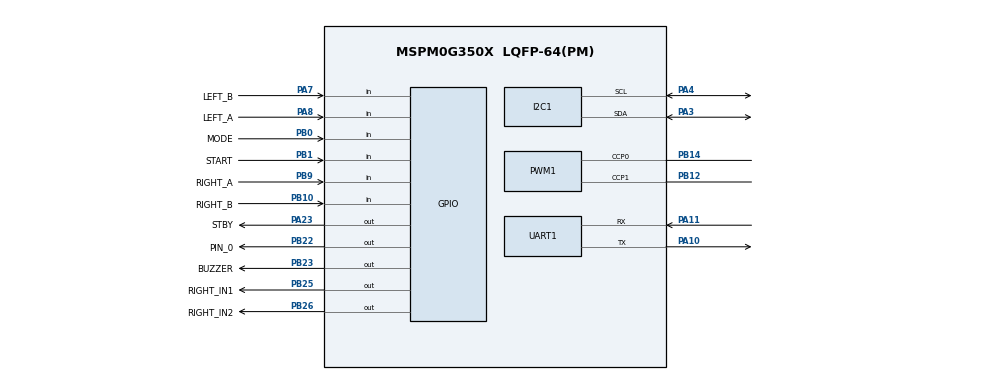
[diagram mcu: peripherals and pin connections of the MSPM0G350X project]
/**
 * @cliArgs --device "MSPM0G350X" --part "Default" --package "LQFP-64(PM)" --product "mspm0_sdk@2.10.00.04"
 * @versions {"tool":"1.27.1+4634"}
 */

/**
 * Import the modules used in this configuration.
 */
const GPIO          = scripting.addModule("/ti/driverlib/GPIO", {}, false);
const GPIO1         = GPIO.addInstance();
const GPIO2         = GPIO.addInstance();
const GPIO3         = GPIO.addInstance();
const GPIO4         = GPIO.addInstance();
const GPIO5         = GPIO.addInstance();
const GPIO6         = GPIO.addInstance();
const GPIO7         = GPIO.addInstance();
const GPIO8         = GPIO.addInstance();
const I2C           = scripting.addModule("/ti/driverlib/I2C", {}, false);
const I2C1          = I2C.addInstance();
const PWM           = scripting.addModule("/ti/driverlib/PWM", {}, false);
const PWM1          = PWM.addInstance();
const SYSCTL        = scripting.addModule("/ti/driverlib/SYSCTL");
const TIMER         = scripting.addModule("/ti/driverlib/TIMER", {}, false);
const TIMER1        = TIMER.addInstance();
const UART          = scripting.addModule("/ti/driverlib/UART", {}, false);
const UART1         = UART.addInstance();
const ProjectConfig = scripting.addModule("/ti/project_config/ProjectConfig");

/**
 * Write custom configuration values to the imported modules.
 */
GPIO1.$name                              = "MOTOR_LEFT";
GPIO1.port                               = "PORTA";
GPIO1.associatedPins.create(2);
GPIO1.associatedPins[0].assignedPin      = "24";
GPIO1.associatedPins[0].$name            = "LEFT_IN1";
GPIO1.associatedPins[0].internalResistor = "PULL_UP";
GPIO1.associatedPins[1].assignedPin      = "25";
GPIO1.associatedPins[1].$name            = "LEFT_IN2";
GPIO1.associatedPins[1].internalResistor = "PULL_UP";

const Board = scripting.addModule("/ti/driverlib/Board", {}, false);

GPIO2.$name                              = "MOTOR_RIGHT";
GPIO2.port                               = "PORTB";
GPIO2.associatedPins.create(2);
GPIO2.associatedPins[0].$name            = "RIGHT_IN1";
GPIO2.associatedPins[0].assignedPin      = "25";
GPIO2.associatedPins[0].internalResistor = "PULL_UP";
GPIO2.associatedPins[0].pin.$assign      = "PB25";
GPIO2.associatedPins[1].$name            = "RIGHT_IN2";
GPIO2.associatedPins[1].assignedPin      = "26";
GPIO2.associatedPins[1].internalResistor = "PULL_UP";
GPIO2.associatedPins[1].pin.$assign      = "PB26";

GPIO3.$name                          = "MOTOR_ENABLE";
GPIO3.port                           = "PORTA";
GPIO3.associatedPins[0].$name        = "STBY";
GPIO3.associatedPins[0].assignedPin  = "23";
GPIO3.associatedPins[0].initialValue = "SET";
GPIO3.associatedPins[0].pin.$assign  = "PA23";

GPIO4.$name                               = "ENCODER_LEFT";
GPIO4.port                                = "PORTA";
GPIO4.associatedPins.create(2);
GPIO4.associatedPins[0].$name             = "LEFT_A";
GPIO4.associatedPins[0].direction         = "INPUT";
GPIO4.associatedPins[0].assignedPin       = "8";
GPIO4.associatedPins[0].internalResistor  = "PULL_UP";
GPIO4.associatedPins[0].interruptEn       = true;
GPIO4.associatedPins[0].interruptPriority = "1";
GPIO4.associatedPins[0].polarity          = "RISE_FALL";
GPIO4.associatedPins[0].pin.$assign       = "PA8";
GPIO4.associatedPins[1].$name             = "LEFT_B";
GPIO4.associatedPins[1].direction         = "INPUT";
GPIO4.associatedPins[1].assignedPin       = "7";
GPIO4.associatedPins[1].internalResistor  = "PULL_UP";
GPIO4.associatedPins[1].interruptEn       = true;
GPIO4.associatedPins[1].interruptPriority = "1";
GPIO4.associatedPins[1].polarity          = "RISE_FALL";
GPIO4.associatedPins[1].pin.$assign       = "PA7";

GPIO5.$name                               = "ENCODER_RIGHT";
GPIO5.port                                = "PORTB";
GPIO5.associatedPins.create(2);
GPIO5.associatedPins[0].$name             = "RIGHT_A";
GPIO5.associatedPins[0].direction         = "INPUT";
GPIO5.associatedPins[0].assignedPin       = "9";
GPIO5.associatedPins[0].internalResistor  = "PULL_UP";
GPIO5.associatedPins[0].interruptEn       = true;
GPIO5.associatedPins[0].interruptPriority = "1";
GPIO5.associatedPins[0].polarity          = "RISE_FALL";
GPIO5.associatedPins[0].pin.$assign       = "PB9";
GPIO5.associatedPins[1].$name             = "RIGHT_B";
GPIO5.associatedPins[1].direction         = "INPUT";
GPIO5.associatedPins[1].assignedPin       = "10";
GPIO5.associatedPins[1].internalResistor  = "PULL_UP";
GPIO5.associatedPins[1].interruptEn       = true;
GPIO5.associatedPins[1].interruptPriority = "1";
GPIO5.associatedPins[1].polarity          = "RISE_FALL";
GPIO5.associatedPins[1].pin.$assign       = "PB10";

GPIO6.$name                              = "LED";
GPIO6.port                               = "PORTB";
GPIO6.associatedPins[0].$name            = "PIN_0";
GPIO6.associatedPins[0].internalResistor = "PULL_UP";
GPIO6.associatedPins[0].initialValue     = "SET";
GPIO6.associatedPins[0].pin.$assign      = "PB22";

GPIO7.$name                              = "H2024_BUTTONS";
GPIO7.port                               = "PORTB";
GPIO7.associatedPins.create(2);
GPIO7.associatedPins[0].$name            = "MODE";
GPIO7.associatedPins[0].direction        = "INPUT";
GPIO7.associatedPins[0].assignedPin      = "0";
GPIO7.associatedPins[0].internalResistor = "PULL_UP";
GPIO7.associatedPins[0].pin.$assign      = "PB0";
GPIO7.associatedPins[1].$name            = "START";
GPIO7.associatedPins[1].direction        = "INPUT";
GPIO7.associatedPins[1].assignedPin      = "1";
GPIO7.associatedPins[1].internalResistor = "PULL_UP";
GPIO7.associatedPins[1].pin.$assign      = "PB1";

GPIO8.$name                              = "H2024_SIGNAL";
GPIO8.port                               = "PORTB";
GPIO8.associatedPins[0].$name            = "BUZZER";
GPIO8.associatedPins[0].assignedPin      = "23";
GPIO8.associatedPins[0].initialValue     = "CLEARED";
GPIO8.associatedPins[0].pin.$assign      = "PB23";

I2C1.basicEnableController             = true;
I2C1.$name                             = "I2C_1";
I2C1.basicClockSourceDivider           = 8;
I2C1.peripheral.$assign                = "I2C1";
I2C1.peripheral.sdaPin.$assign         = "PA3";
I2C1.peripheral.sclPin.$assign         = "PA4";
I2C1.sdaPinConfig.hideOutputInversion  = scripting.forceWrite(false);
I2C1.sdaPinConfig.onlyInternalResistor = scripting.forceWrite(false);
I2C1.sdaPinConfig.passedPeripheralType = scripting.forceWrite("Digital");
I2C1.sdaPinConfig.$name                = "ti_driverlib_gpio_GPIOPinGeneric7";
I2C1.sdaPinConfig.internalResistor     = "PULL_UP";
I2C1.sclPinConfig.hideOutputInversion  = scripting.forceWrite(false);
I2C1.sclPinConfig.onlyInternalResistor = scripting.forceWrite(false);
I2C1.sclPinConfig.passedPeripheralType = scripting.forceWrite("Digital");
I2C1.sclPinConfig.$name                = "ti_driverlib_gpio_GPIOPinGeneric8";
I2C1.sclPinConfig.internalResistor     = "PULL_UP";

PWM1.$name                          = "PWM_0";
PWM1.pwmMode                        = "EDGE_ALIGN_UP";
PWM1.enableShadowLoad               = true;
PWM1.interruptPriority              = "0";
PWM1.clockPrescale                  = 4;
PWM1.peripheral.$assign             = "TIMA0";
PWM1.peripheral.ccp0Pin.$assign     = "PB14";
PWM1.peripheral.ccp1Pin.$assign     = "PB12";
PWM1.PWM_CHANNEL_0.$name            = "ti_driverlib_pwm_PWMTimerCC0";
PWM1.PWM_CHANNEL_1.$name            = "ti_driverlib_pwm_PWMTimerCC1";
PWM1.PWM_CHANNEL_1.shadowUpdateMode = "ZERO_EVT";
PWM1.ccp0PinConfig.$name            = "ti_driverlib_gpio_GPIOPinGeneric4";
PWM1.ccp1PinConfig.$name            = "ti_driverlib_gpio_GPIOPinGeneric5";

SYSCTL.clockTreeEn = true;

TIMER1.$name              = "TIMER_0";
TIMER1.timerClkDiv        = 8;
TIMER1.enableShadowLoad   = true;
TIMER1.timerClkPrescale   = 256;
TIMER1.timerMode          = "PERIODIC";
TIMER1.timerPeriod        = "10ms";
TIMER1.interrupts         = ["ZERO"];
TIMER1.interruptPriority  = "0";
TIMER1.peripheral.$assign = "TIMA1";

UART1.$name                    = "UART_0";
UART1.targetBaudRate           = 115200;
UART1.enableFIFO               = true;
UART1.rxFifoThreshold          = "DL_UART_RX_FIFO_LEVEL_ONE_ENTRY";
UART1.enableDMARX              = false;
UART1.enableDMATX              = false;
UART1.enabledInterrupts        = ["RX"];
UART1.interruptPriority        = "1";
UART1.peripheral.$assign       = "UART0";
UART1.peripheral.rxPin.$assign = "PA11";
UART1.peripheral.txPin.$assign = "PA10";
UART1.txPinConfig.$name        = "ti_driverlib_gpio_GPIOPinGeneric6";
UART1.rxPinConfig.$name        = "ti_driverlib_gpio_GPIOPinGeneric1";

ProjectConfig.genDisable = true;

/**
 * Pinmux solution for unlocked pins/peripherals. This ensures that minor changes to the automatic solver in a future
 * version of the tool will not impact the pinmux you originally saw.  These lines can be completely deleted in order to
 * re-solve from scratch.
 */
GPIO1.associatedPins[0].pin.$suggestSolution = "PA24";
GPIO1.associatedPins[1].pin.$suggestSolution = "PA25";
Board.peripheral.$suggestSolution            = "DEBUGSS";
Board.peripheral.swclkPin.$suggestSolution   = "PA20";
Board.peripheral.swdioPin.$suggestSolution   = "PA19";
